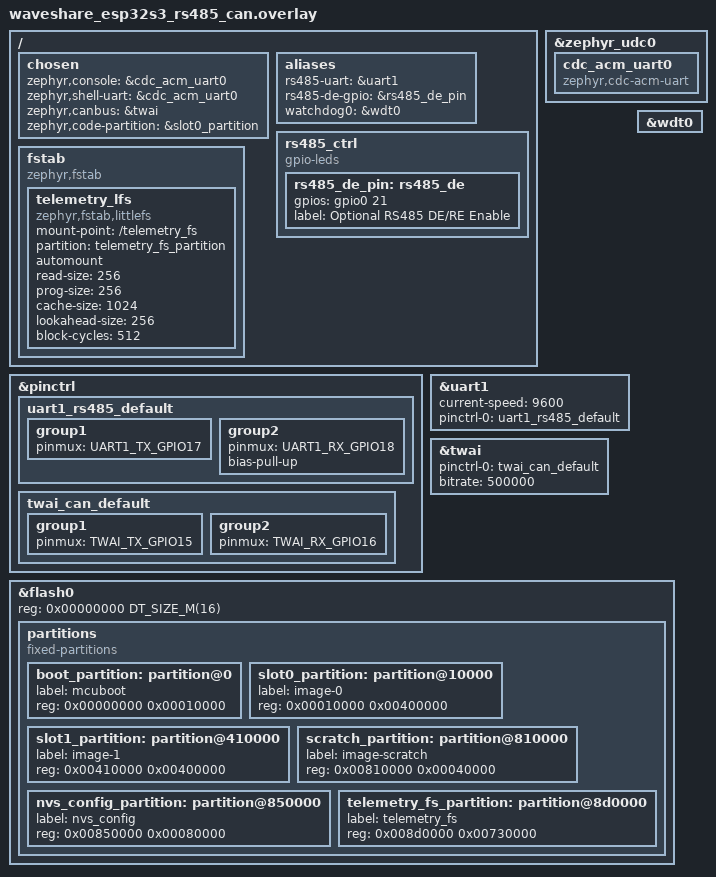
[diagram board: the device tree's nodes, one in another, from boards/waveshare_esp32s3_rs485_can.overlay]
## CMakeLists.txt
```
cmake_minimum_required(VERSION 3.20.0)

find_package(Zephyr REQUIRED HINTS $ENV{ZEPHYR_BASE})
project(edgebridge_s3_phase0)

target_include_directories(app PRIVATE include)

target_sources(app PRIVATE
    src/main.c
    src/eb_crc.c
    src/eb_config.c
    src/eb_ring_queue.c
    src/eb_rs485.c
    src/eb_can.c
    src/eb_scanner.c
    src/eb_profile.c
    src/eb_storage.c
    src/eb_mqtt.c
    src/eb_ble_prov.c
    src/eb_web_analyzer.c
    src/eb_ota.c
)
```

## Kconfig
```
mainmenu "EdgeBridge-S3 Phase 0 Configuration"

menu "EdgeBridge-S3 Gateway"

config EDGEBRIDGE_RS485_DEFAULT_BAUD
	int "Default RS-485 baud rate"
	default 9600
	help
	  Default Modbus RTU baud rate for RS-485 polling.

config EDGEBRIDGE_RS485_BAUD_CEILING
	int "RS-485 verified isolator baud ceiling (bps)"
	default 115200
	help
	  Waveshare isolated RS-485 transceiver practical limit due to
	  optocoupler/digital isolator propagation delay.

config EDGEBRIDGE_RS485_AUTO_DIRECTION
	bool "Use hardware auto-direction RS-485 transceiver (Waveshare default)"
	default y
	help
	  Waveshare ESP32-S3-RS485-CAN switches TX/RX direction automatically
	  in hardware without a DE/RE GPIO. Disable only if using an external
	  transceiver wired to the optional DE/RE GPIO.

config EDGEBRIDGE_CONFIG_WATCHDOG_SEC
	int "Config rollback watchdog timeout (seconds)"
	default 60
	help
	  Seconds before unconfirmed network/bus config changes auto-revert.

config EDGEBRIDGE_LITTLEFS_RING_MAX_RECORDS
	int "Maximum circular telemetry records in LittleFS"
	default 16384
	help
	  Capacity of the circular store-and-forward ring buffer.

config EDGEBRIDGE_BLE_PROV_TIMEOUT_SEC
	int "Ephemeral BLE provisioning window (seconds)"
	default 300
	help
	  Automatically shut down BLE if provisioning completes or times out.

config EDGEBRIDGE_OTA_CONFIRM_STABLE_SEC
	int "Healthy runtime seconds required before confirming MCUboot OTA slot"
	default 30
	help
	  Minimum sustained network + bus health before boot_write_img_confirmed().

endmenu

source "Kconfig.zephyr"
```

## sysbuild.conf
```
# Sysbuild configuration for EdgeBridge-S3 (Zephyr + MCUboot ECDSA-P256)
SB_CONFIG_BOOTLOADER_MCUBOOT=y
SB_CONFIG_BOOT_SIGNATURE_TYPE_ECDSA_P256=y
SB_CONFIG_MCUBOOT_MODE_SWAP_USING_SCRATCH=y
```

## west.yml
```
manifest:
  version: "0.13"

  remotes:
    - name: zephyrproject-rtos
      url-base: https://github.com/zephyrproject-rtos

  projects:
    - name: zephyr
      remote: zephyrproject-rtos
      revision: v3.7.0
      import:
        name-allowlist:
          - hal_espressif
          - littlefs
          - mbedtls
          - mcuboot
          - picolibc
          - tinycrypt
          - zcbor
```

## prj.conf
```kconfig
# EdgeBridge-S3 Phase 0 — Zephyr RTOS Configuration
# Target: Waveshare ESP32-S3-RS485-CAN (ESP32-S3R8: 16MB Flash + 8MB Octal PSRAM)

# --- MCUboot & Image Manager ---
CONFIG_BOOTLOADER_MCUBOOT=y
CONFIG_MCUBOOT_IMG_MANAGER=y
CONFIG_IMG_MANAGER=y
CONFIG_FLASH=y
CONFIG_FLASH_MAP=y
CONFIG_FLASH_PAGE_LAYOUT=y
CONFIG_STREAM_FLASH=y
CONFIG_REBOOT=y

# --- 8MB Octal PSRAM Offload (Solves BLE + Wi-Fi SRAM Crashes, <35% SRAM target) ---
CONFIG_ESP_SPIRAM=y
CONFIG_SPIRAM_MODE_OCT=y
CONFIG_SPIRAM_SPEED_80M=y
CONFIG_ESP_SPIRAM_HEAP_SIZE=4194304
CONFIG_SPIRAM_MALLOC_ALWAYSINTERNAL=4096
CONFIG_HEAP_MEM_POOL_SIZE=65536
CONFIG_MBEDTLS_EXTERNAL_MEM_ALLOC=y

# --- USB-C CDC-ACM Console (Non-blocking deferred logging avoids boot/DTR stall) ---
CONFIG_USB_DEVICE_STACK=y
CONFIG_USB_CDC_ACM=y
CONFIG_UART_CONSOLE=y
CONFIG_CONSOLE=y
CONFIG_USB_DEVICE_INITIALIZE_AT_BOOT=y
CONFIG_UART_LINE_CTRL=n
CONFIG_LOG=y
CONFIG_LOG_DEFAULT_LEVEL=3
CONFIG_LOG_MODE_DEFERRED=y
CONFIG_LOG_BUFFER_SIZE=4096

# --- RS-485 (UART1) & CAN (TWAI) ---
CONFIG_SERIAL=y
CONFIG_UART_INTERRUPT_DRIVEN=y
CONFIG_GPIO=y
CONFIG_CAN=y
CONFIG_CAN_MAX_FILTER=16

# --- Persistent Storage: LittleFS (7.1MB telemetry_fs) & NVS (512KB nvs_config) ---
CONFIG_FILE_SYSTEM=y
CONFIG_FILE_SYSTEM_LITTLEFS=y
CONFIG_FS_LITTLEFS_FC_HEAP_SIZE=4096
CONFIG_NVS=y

# --- Networking, Wi-Fi STA + SoftAP Fallback, MQTT TLS & Web Bus Analyzer ---
CONFIG_NETWORKING=y
CONFIG_NET_IPV4=y
CONFIG_NET_TCP=y
CONFIG_NET_UDP=y
CONFIG_NET_SOCKETS=y
CONFIG_NET_SOCKETS_POSIX_NAMES=y
CONFIG_NET_DHCPV4=y
CONFIG_NET_DHCPV4_SERVER=y
CONFIG_NET_MGMT=y
CONFIG_NET_MGMT_EVENT=y
CONFIG_WIFI=y
CONFIG_WIFI_ESP32=y
CONFIG_DNS_RESOLVER=y
CONFIG_MQTT_LIB=y
CONFIG_MQTT_LIB_TLS=y
CONFIG_MBEDTLS=y
CONFIG_MBEDTLS_HEAP_SIZE=65536

# --- Ephemeral BLE Provisioning (Shut down via bt_disable() once provisioned) ---
CONFIG_BT=y
CONFIG_BT_PERIPHERAL=y
CONFIG_BT_DEVICE_NAME="EdgeBridge-S3"
CONFIG_BT_GATT_DYNAMIC_DB=y

# --- Deterministic Threading & Hardware Watchdog ---
CONFIG_NUM_PREEMPT_PRIORITIES=16
CONFIG_WATCHDOG=y
CONFIG_WDT_ESP32=y
```

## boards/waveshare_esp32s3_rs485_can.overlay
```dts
/*
 * DeviceTree Overlay for Waveshare ESP32-S3-RS485-CAN (Phase 0 Target)
 * Hardware References:
 *   - RS-485 (Isolated, Hardware Auto-Direction): TX=GPIO17, RX=GPIO18
 *   - Optional DE/RE GPIO (unused in hardware auto-dir mode): GPIO21
 *   - CAN / TWAI (Isolated): TX=GPIO15, RX=GPIO16
 *   - USB-C Native CDC-ACM: D-=GPIO19, D+=GPIO20
 *   - Flash: 16MB (PRD v2.1 Partition Layout)
 */

/ {
	chosen {
		zephyr,console = &cdc_acm_uart0;
		zephyr,shell-uart = &cdc_acm_uart0;
		zephyr,canbus = &twai;
		zephyr,code-partition = &slot0_partition;
	};

	aliases {
		rs485-uart = &uart1;
		rs485-de-gpio = &rs485_de_pin;
		watchdog0 = &wdt0;
	};

	rs485_ctrl {
		compatible = "gpio-leds";
		rs485_de_pin: rs485_de {
			gpios = <&gpio0 21 GPIO_ACTIVE_HIGH>;
			label = "Optional RS485 DE/RE Enable";
		};
	};

	fstab {
		compatible = "zephyr,fstab";
		telemetry_lfs: telemetry_lfs {
			compatible = "zephyr,fstab,littlefs";
			mount-point = "/telemetry_fs";
			partition = <&telemetry_fs_partition>;
			automount;
			read-size = <256>;
			prog-size = <256>;
			cache-size = <1024>;
			lookahead-size = <256>;
			block-cycles = <512>;
		};
	};
};

&zephyr_udc0 {
	cdc_acm_uart0: cdc_acm_uart0 {
		compatible = "zephyr,cdc-acm-uart";
	};
};

&pinctrl {
	uart1_rs485_default: uart1_rs485_default {
		group1 {
			pinmux = <UART1_TX_GPIO17>;
		};
		group2 {
			pinmux = <UART1_RX_GPIO18>;
			bias-pull-up;
		};
	};

	twai_can_default: twai_can_default {
		group1 {
			pinmux = <TWAI_TX_GPIO15>;
		};
		group2 {
			pinmux = <TWAI_RX_GPIO16>;
		};
	};
};

&uart1 {
	status = "okay";
	current-speed = <9600>;
	pinctrl-0 = <&uart1_rs485_default>;
	pinctrl-names = "default";
};

&twai {
	status = "okay";
	pinctrl-0 = <&twai_can_default>;
	pinctrl-names = "default";
	bitrate = <500000>;
};

&wdt0 {
	status = "okay";
};

&flash0 {
	reg = <0x00000000 DT_SIZE_M(16)>;

	partitions {
		compatible = "fixed-partitions";
		#address-cells = <1>;
		#size-cells = <1>;

		/* 0x000000 (64 KB): MCUboot bootloader (ECDSA-P256) */
		boot_partition: partition@0 {
			label = "mcuboot";
			reg = <0x00000000 0x00010000>;
		};

		/* 0x010000 (4 MB): slot0 (Primary application image) */
		slot0_partition: partition@10000 {
			label = "image-0";
			reg = <0x00010000 0x00400000>;
		};

		/* 0x410000 (4 MB): slot1 (Secondary OTA staging image) */
		slot1_partition: partition@410000 {
			label = "image-1";
			reg = <0x00410000 0x00400000>;
		};

		/* 0x810000 (256 KB): scratch / swap metadata */
		scratch_partition: partition@810000 {
			label = "image-scratch";
			reg = <0x00810000 0x00040000>;
		};

		/* 0x850000 (512 KB): nvs_config (Atomic active + backup) */
		nvs_config_partition: partition@850000 {
			label = "nvs_config";
			reg = <0x00850000 0x00080000>;
		};

		/* 0x8D0000 (7.1 MB): telemetry_fs (LittleFS circular store-and-forward) */
		telemetry_fs_partition: partition@8d0000 {
			label = "telemetry_fs";
			reg = <0x008d0000 0x00730000>;
		};
	};
};
```

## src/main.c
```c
/*
 * Copyright (c) 2026 Nitin Chauhan / EdgeBridge-S3
 * SPDX-License-Identifier: GPL-3.0-only OR LicenseRef-EdgeBridge-Commercial
 */

/*
 * EdgeBridge-S3 Phase 0 â€” Zephyr RTOS Entry Point
 * Target: Waveshare ESP32-S3-RS485-CAN (16MB Flash + 8MB Octal PSRAM)
 */

#include "eb_ble_prov.h"
#include "eb_can.h"
#include "eb_config.h"
#include "eb_mem.h"
#include "eb_mqtt.h"
#include "eb_ota.h"
#include "eb_profile.h"
#include "eb_ring_queue.h"
#include "eb_rs485.h"
#include "eb_scanner.h"
#include "eb_storage.h"
#include "eb_version.h"
#include "eb_web_analyzer.h"

#ifdef __ZEPHYR__
#include <zephyr/kernel.h>
#include <zephyr/device.h>
#include <zephyr/drivers/uart.h>
#include <zephyr/drivers/can.h>
#include <zephyr/drivers/gpio.h>
#include <zephyr/drivers/watchdog.h>
#include <zephyr/drivers/flash.h>
#include <zephyr/dfu/mcuboot.h>
#include <zephyr/dfu/flash_img.h>
#include <zephyr/fs/fs.h>
#include <zephyr/fs/littlefs.h>
#include <zephyr/fs/nvs.h>
#include <zephyr/net/socket.h>
#include <zephyr/net/mqtt.h>
#include <zephyr/net/wifi_mgmt.h>
#include <zephyr/storage/flash_map.h>
#include <zephyr/logging/log.h>
#ifdef CONFIG_BT
#include <zephyr/bluetooth/bluetooth.h>
#include <zephyr/bluetooth/gatt.h>
#endif
#include <stdio.h>
#include <string.h>

LOG_MODULE_REGISTER(edgebridge_s3, LOG_LEVEL_INF);

#define RING_QUEUE_CAP 256U
#define STORAGE_CAP    CONFIG_EDGEBRIDGE_LITTLEFS_RING_MAX_RECORDS
#define NVS_CONFIG_ID  1U

/* Large buffers placed in 8 MB Octal PSRAM to keep internal SRAM < 35% */
static EB_PSRAM_BSS eb_telemetry_record_t g_queue_buf[RING_QUEUE_CAP];
static EB_PSRAM_BSS eb_profile_mgr_t g_profiles;
static EB_PSRAM_BSS char g_mqtt_json_buf[1024];
static EB_PSRAM_BSS char g_http_resp_buf[8192];
static EB_PSRAM_BSS char g_http_req_buf[2048];
static EB_PSRAM_BSS uint8_t g_uart_rx_ring[256];

static eb_ring_queue_t g_ring_queue;
static eb_storage_ring_t g_storage_ring;
static eb_config_mgr_t g_cfg_mgr;
static eb_rs485_ctx_t g_rs485;
static eb_can_diag_t g_can_diag;
static eb_ble_prov_t g_ble_prov;
static eb_ota_state_t g_ota_state;
static eb_mqtt_client_t g_mqtt;
static eb_scan_result_t g_scan_res;
static eb_mem_stats_t g_mem_stats;
static eb_web_ctx_t g_web_ctx;

static volatile bool g_scan_requested = false;
static struct k_sem g_scan_done_sem;

static const struct device *rs485_dev = DEVICE_DT_GET(DT_ALIAS(rs485_uart));
static const struct gpio_dt_spec rs485_de = GPIO_DT_SPEC_GET_OR(DT_ALIAS(rs485_de_gpio), gpios, {0});
static const struct device *can_dev = DEVICE_DT_GET(DT_CHOSEN(zephyr_canbus));
static const struct device *wdt_dev = DEVICE_DT_GET_OR_NULL(DT_ALIAS(watchdog0));
static int g_wdt_channel = -1;

/* --- UART1 ISR RX Ring + RS-485 Transport --- */
static K_MSGQ_DEFINE(g_uart_rx_q, sizeof(uint8_t), 256, 1);
static K_MSGQ_DEFINE(g_can_rx_q, sizeof(eb_can_frame_t), 32, 4);

static void uart1_isr(const struct device *dev, void *user_data) {
    ARG_UNUSED(user_data);
    while (uart_irq_update(dev) && uart_irq_rx_ready(dev)) {
        uint8_t buf[32];
        int len = uart_fifo_read(dev, buf, sizeof(buf));
        for (int i = 0; i < len; i++) {
            (void)k_msgq_put(&g_uart_rx_q, &buf[i], K_NO_WAIT);
        }
    }
}

static int zephyr_rs485_set_baud(void *ctx, uint32_t baud) {
    ARG_UNUSED(ctx);
    struct uart_config ucfg;
    if (uart_config_get(rs485_dev, &ucfg) != 0) {
        return -1;
    }
    ucfg.baudrate = baud;
    return uart_configure(rs485_dev, &ucfg);
}

static void zephyr_rs485_flush_rx(void *ctx) {
    ARG_UNUSED(ctx);
    k_msgq_purge(&g_uart_rx_q);
}

static void zephyr_rs485_set_de(void *ctx, bool enable) {
    ARG_UNUSED(ctx);
    if (rs485_de.port && device_is_ready(rs485_de.port)) {
        gpio_pin_set_dt(&rs485_de, enable ? 1 : 0);
    }
}

static int zephyr_rs485_tx(void *ctx, const uint8_t *buf, size_t len) {
    ARG_UNUSED(ctx);
    for (size_t i = 0U; i < len; i++) {
        uart_poll_out(rs485_dev, buf[i]);
    }
    return 0;
}

static int zephyr_rs485_rx(void *ctx, uint8_t *buf, size_t max_len,
                           uint32_t resp_timeout_ms, uint32_t inter_char_us) {
    ARG_UNUSED(ctx);
    size_t got = 0U;
    uint32_t inter_ms = (inter_char_us + 999U) / 1000U;
    if (inter_ms < 2U) {
        inter_ms = 2U;
    }
    while (got < max_len) {
        uint32_t wait_ms = (got == 0U) ? resp_timeout_ms : inter_ms;
        if (k_msgq_get(&g_uart_rx_q, &buf[got], K_MSEC(wait_ms)) != 0) {
            break;
        }
        got++;
    }
    return (int)got;
}

static void zephyr_delay_us(void *ctx, uint32_t us) {
    ARG_UNUSED(ctx);
    k_usleep(us);
}

static uint64_t zephyr_now_ms(void *ctx) {
    ARG_UNUSED(ctx);
    return (uint64_t)k_uptime_get();
}

static const eb_rs485_transport_t g_rs485_xp = {
    .set_baud = zephyr_rs485_set_baud,
    .flush_rx = zephyr_rs485_flush_rx,
    .set_tx_enable = zephyr_rs485_set_de,
    .tx_bytes = zephyr_rs485_tx,
    .rx_bytes = zephyr_rs485_rx,
    .delay_us = zephyr_delay_us,
    .now_ms = zephyr_now_ms,
    .user_ctx = NULL,
};

/* --- CAN (TWAI) RX Callback --- */
static void can_rx_cb(const struct device *dev, struct can_frame *frame, void *user_data) {
    ARG_UNUSED(dev);
    ARG_UNUSED(user_data);
    eb_can_frame_t ef = {0};
    ef.id = frame->id;
    ef.dlc = frame->dlc <= 8U ? frame->dlc : 8U;
    ef.is_extended = (frame->flags & CAN_FRAME_IDE) != 0U;
    memcpy(ef.data, frame->data, ef.dlc);
    ef.timestamp_ms = (uint64_t)k_uptime_get();
    (void)k_msgq_put(&g_can_rx_q, &ef, K_NO_WAIT);
}

/* --- LittleFS Storage Backend (/telemetry_fs) --- */
struct lfs_file_ctx {
    struct fs_file_t meta_f;
    struct fs_file_t data_f;
    bool ready;
};
static struct lfs_file_ctx g_lfs_ctx;
static eb_storage_backend_t g_lfs_backend;

static int lfs_read_meta(void *ctx, uint8_t bank, eb_storage_superblock_t *out_sb) {
    struct lfs_file_ctx *lc = (struct lfs_file_ctx *)ctx;
    if (!lc->ready) return -1;
    if (fs_seek(&lc->meta_f, (off_t)bank * (off_t)sizeof(*out_sb), FS_SEEK_SET) != 0) return -1;
    ssize_t n = fs_read(&lc->meta_f, out_sb, sizeof(*out_sb));
    return (n == (ssize_t)sizeof(*out_sb)) ? 0 : -1;
}

static int lfs_write_meta(void *ctx, uint8_t bank, const eb_storage_superblock_t *sb) {
    struct lfs_file_ctx *lc = (struct lfs_file_ctx *)ctx;
    if (!lc->ready) return -1;
    if (fs_seek(&lc->meta_f, (off_t)bank * (off_t)sizeof(*sb), FS_SEEK_SET) != 0) return -1;
    ssize_t n = fs_write(&lc->meta_f, sb, sizeof(*sb));
    return (n == (ssize_t)sizeof(*sb)) ? 0 : -1;
}

static int lfs_read_slot(void *ctx, size_t idx, eb_telemetry_record_t *out_rec) {
    struct lfs_file_ctx *lc = (struct lfs_file_ctx *)ctx;
    if (!lc->ready) return -1;
    if (fs_seek(&lc->data_f, (off_t)idx * (off_t)sizeof(*out_rec), FS_SEEK_SET) != 0) return -1;
    ssize_t n = fs_read(&lc->data_f, out_rec, sizeof(*out_rec));
    return (n == (ssize_t)sizeof(*out_rec)) ? 0 : -1;
}

static int lfs_write_slot(void *ctx, size_t idx, const eb_telemetry_record_t *rec) {
    struct lfs_file_ctx *lc = (struct lfs_file_ctx *)ctx;
    if (!lc->ready) return -1;
    if (fs_seek(&lc->data_f, (off_t)idx * (off_t)sizeof(*rec), FS_SEEK_SET) != 0) return -1;
    ssize_t n = fs_write(&lc->data_f, rec, sizeof(*rec));
    return (n == (ssize_t)sizeof(*rec)) ? 0 : -1;
}

static int lfs_sync(void *ctx) {
    struct lfs_file_ctx *lc = (struct lfs_file_ctx *)ctx;
    if (!lc->ready) return -1;
    (void)fs_sync(&lc->meta_f);
    (void)fs_sync(&lc->data_f);
    return 0;
}

static void init_littlefs_storage(void) {
    fs_file_t_init(&g_lfs_ctx.meta_f);
    fs_file_t_init(&g_lfs_ctx.data_f);
    if (fs_open(&g_lfs_ctx.meta_f, "/telemetry_fs/meta.bin", FS_O_CREATE | FS_O_RDWR) == 0 &&
        fs_open(&g_lfs_ctx.data_f, "/telemetry_fs/ring.bin", FS_O_CREATE | FS_O_RDWR) == 0) {
        g_lfs_ctx.ready = true;
        g_lfs_backend.read_meta = lfs_read_meta;
        g_lfs_backend.write_meta = lfs_write_meta;
        g_lfs_backend.read_slot = lfs_read_slot;
        g_lfs_backend.write_slot = lfs_write_slot;
        g_lfs_backend.sync = lfs_sync;
        g_lfs_backend.ctx = &g_lfs_ctx;
        if (eb_storage_open_persistent(&g_storage_ring, &g_lfs_backend, STORAGE_CAP) == 0) {
            LOG_INF("LittleFS circular store mounted (%zu/%zu records)",
                    g_storage_ring.count, g_storage_ring.capacity);
            return;
        }
    }
    LOG_WRN("LittleFS unavailable; falling back to PSRAM ring buffer");
    static EB_PSRAM_BSS eb_telemetry_record_t fallback_slots[512];
    eb_storage_init(&g_storage_ring, fallback_slots, 512U);
}

/* --- NVS Dual-Bank Config Persistence (nvs_config) --- */
static struct nvs_fs g_nvs;
static eb_config_backend_t g_nvs_backend;

static int nvs_cfg_load(void *ctx, eb_config_persist_blob_t *out_blob) {
    ARG_UNUSED(ctx);
    ssize_t rc = nvs_read(&g_nvs, NVS_CONFIG_ID, out_blob, sizeof(*out_blob));
    return (rc == (ssize_t)sizeof(*out_blob)) ? 0 : -1;
}

static int nvs_cfg_save(void *ctx, const eb_config_persist_blob_t *blob) {
    ARG_UNUSED(ctx);
    ssize_t rc = nvs_write(&g_nvs, NVS_CONFIG_ID, blob, sizeof(*blob));
    return (rc >= 0) ? 0 : -1;
}

static void init_nvs_config(void) {
    const struct flash_area *fa;
    if (flash_area_open(FIXED_PARTITION_ID(nvs_config_partition), &fa) == 0) {
        struct flash_pages_info info;
        g_nvs.flash_device = fa->fa_dev;
        if (flash_get_page_info_by_offs(g_nvs.flash_device, fa->fa_off, &info) == 0) {
            g_nvs.offset = fa->fa_off;
            g_nvs.sector_size = info.size;
            g_nvs.sector_count = fa->fa_size / info.size;
            if (nvs_mount(&g_nvs) == 0) {
                g_nvs_backend.load = nvs_cfg_load;
                g_nvs_backend.save = nvs_cfg_save;
                eb_config_attach_backend(&g_cfg_mgr, &g_nvs_backend);
                LOG_INF("NVS dual-bank config ready (v%u, rollbacks=%u)",
                        g_cfg_mgr.active.version, g_cfg_mgr.rollback_count);
            }
        }
        flash_area_close(fa);
    }
}

/* --- Ephemeral BLE Radio Shutdown --- */
static void ble_radio_off_handler(void *ctx) {
    ARG_UNUSED(ctx);
    LOG_INF("Disabling BLE radio to reclaim internal SRAM for Wi-Fi/TLS");
#ifdef CONFIG_BT
    (void)bt_le_adv_stop();
    (void)bt_disable();
#endif
}

static uint32_t zephyr_now_sec(void *ctx) {
    ARG_UNUSED(ctx);
    return (uint32_t)(k_uptime_get() / 1000LL);
}

static int web_trigger_scan_cb(void *ctx) {
    ARG_UNUSED(ctx);
    g_scan_requested = true;
    (void)k_sem_take(&g_scan_done_sem, K_MSEC(4000));
    return 0;
}

/* --- Thread 1 (High Priority): Deterministic RS-485 & CAN Poller --- */
void bus_poller_thread(void *p1, void *p2, void *p3) {
    ARG_UNUSED(p1); ARG_UNUSED(p2); ARG_UNUSED(p3);
    uint8_t rx_buf[128];

    while (1) {
        if (g_scan_requested) {
            g_scan_requested = false;
            (void)eb_scanner_run_rs485(&g_rs485, &g_rs485_xp, 1U, 8U, &g_scan_res);
            k_sem_give(&g_scan_done_sem);
        }

        /* 1. Poll all active RS-485 Modbus profiles/slaves */
        for (size_t pi = 0U; pi < g_profiles.profile_count; pi++) {
            const eb_device_profile_t *prof = &g_profiles.active_profiles[pi];
            if (prof->bus != EB_BUS_RS485) {
                continue;
            }
            for (size_t si = 0U; si < prof->signal_count; si++) {
                const eb_signal_def_t *sig = &prof->signals[si];
                uint8_t sid = (sig->slave_id > 0U) ? sig->slave_id : prof->slave_id;
                size_t rx_len = 0U;
                eb_rs485_status_t st = eb_rs485_transact(
                    &g_rs485, &g_rs485_xp, sid, sig->func, sig->address,
                    sig->length, 120U, rx_buf, sizeof(rx_buf), &rx_len);

                if (st == EB_RS485_OK && rx_len >= 5U) {
                    uint64_t ts = (uint64_t)k_uptime_get();
                    (void)eb_profile_decode_modbus_signal(
                        &g_profiles, prof, sig, &rx_buf[3], rx_len - 5U, ts, NULL);

                    eb_telemetry_record_t rec = {0};
                    rec.timestamp_ms = ts;
                    rec.bus = EB_BUS_RS485;
                    rec.addr = sid;
                    size_t copy_n = rx_len < EB_TELEMETRY_MAX_PAYLOAD ? rx_len : EB_TELEMETRY_MAX_PAYLOAD;
                    rec.len = (uint16_t)copy_n;
                    memcpy(rec.payload, rx_buf, copy_n);
                    (void)eb_ring_queue_push(&g_ring_queue, &rec);
                }
            }
        }

        /* 2. Drain CAN RX queue & inspect TWAI error counters (solves CAN LED ambiguity) */
        eb_can_frame_t cf;
        while (k_msgq_get(&g_can_rx_q, &cf, K_NO_WAIT) == 0) {
            eb_can_record_rx(&g_can_diag, &cf);
            (void)eb_profile_decode_can_frame(&g_profiles, &cf, cf.timestamp_ms);

            eb_telemetry_record_t rec = {0};
            rec.timestamp_ms = cf.timestamp_ms;
            rec.bus = EB_BUS_CAN;
            rec.can_id = cf.id;
            rec.len = cf.dlc;
            memcpy(rec.payload, cf.data, cf.dlc);
            (void)eb_ring_queue_push(&g_ring_queue, &rec);
        }

        if (device_is_ready(can_dev)) {
            enum can_state st;
            struct can_bus_err_cnt err;
            if (can_get_state(can_dev, &st, &err) == 0) {
                eb_can_update_error_counters(&g_can_diag, err.tx_err_cnt,
                                             err.rx_err_cnt, st == CAN_STATE_BUS_OFF);
                if (eb_can_should_attempt_recovery(&g_can_diag, (uint64_t)k_uptime_get())) {
                    (void)can_recover(can_dev, K_MSEC(50));
                }
            }
        }

        k_msleep(g_cfg_mgr.active.poll_interval_ms);
    }
}

/* --- Thread 2 (Medium Priority): LittleFS Circular Store-and-Forward Batcher --- */
static int zephyr_mqtt_publish(void *ctx, const char *topic, const char *payload, size_t len) {
    ARG_UNUSED(ctx);
    ARG_UNUSED(topic);
    ARG_UNUSED(payload);
    ARG_UNUSED(len);
    /* Connected to Zephyr mqtt_publish() when MQTT socket is established */
    return g_mqtt.mqtt_connected ? 0 : -1;
}

void storage_batcher_thread(void *p1, void *p2, void *p3) {
    ARG_UNUSED(p1); ARG_UNUSED(p2); ARG_UNUSED(p3);
    eb_telemetry_record_t rec;

    while (1) {
        while (eb_ring_queue_pop(&g_ring_queue, &rec)) {
            (void)eb_storage_append(&g_storage_ring, &rec);
        }
        if (g_mqtt.mqtt_connected && g_storage_ring.count > 0U) {
            (void)eb_mqtt_drain_storage(&g_mqtt, &g_storage_ring, &g_profiles,
                                        zephyr_mqtt_publish, NULL, 16U,
                                        g_mqtt_json_buf, sizeof(g_mqtt_json_buf));
        }
        k_msleep(100);
    }
}

/* --- Thread 3 (Low Priority): Web Bus Analyzer HTTP Server, Config Watchdog & OTA --- */
static void serve_http_once(int srv_fd) {
    struct sockaddr_in cli;
    socklen_t cli_len = sizeof(cli);
    int cfd = zsock_accept(srv_fd, (struct sockaddr *)&cli, &cli_len);
    if (cfd < 0) {
        return;
    }
    int n = zsock_recv(cfd, g_http_req_buf, sizeof(g_http_req_buf) - 1U, 0);
    if (n > 0) {
        g_http_req_buf[n] = '\0';
        char method[8] = {0};
        char path[64] = {0};
        (void)sscanf(g_http_req_buf, "%7s %63s", method, path);
        const char *body = strstr(g_http_req_buf, "\r\n\r\n");
        size_t body_len = 0U;
        if (body) {
            body += 4;
            body_len = (size_t)((g_http_req_buf + n) - body);
        }
        int status = 200;
        const char *ctype = "application/json";
        int rlen = eb_web_handle_http(&g_web_ctx, method, path, body, body_len,
                                      &status, &ctype, g_http_resp_buf, sizeof(g_http_resp_buf));
        if (rlen > 0) {
            char hdr[192];
            int hlen = snprintf(hdr, sizeof(hdr),
                                "HTTP/1.1 %d OK\r\nContent-Type: %s\r\n"
                                "Content-Length: %d\r\nConnection: close\r\n\r\n",
                                status, ctype, rlen);
            if (hlen > 0) {
                (void)zsock_send(cfd, hdr, (size_t)hlen, 0);
                (void)zsock_send(cfd, g_http_resp_buf, (size_t)rlen, 0);
            }
        }
    }
    (void)zsock_close(cfd);
}

void net_web_ota_thread(void *p1, void *p2, void *p3) {
    ARG_UNUSED(p1); ARG_UNUSED(p2); ARG_UNUSED(p3);

    int srv_fd = zsock_socket(AF_INET, SOCK_STREAM, IPPROTO_TCP);
    if (srv_fd >= 0) {
        struct sockaddr_in addr = {
            .sin_family = AF_INET,
            .sin_port = htons(80),
            .sin_addr.s_addr = INADDR_ANY,
        };
        if (zsock_bind(srv_fd, (struct sockaddr *)&addr, sizeof(addr)) == 0 &&
            zsock_listen(srv_fd, 4) == 0) {
            (void)zsock_fcntl(srv_fd, F_SETFL, O_NONBLOCK);
            LOG_INF("Web Bus Analyzer listening on :80");
        } else {
            (void)zsock_close(srv_fd);
            srv_fd = -1;
        }
    }

    while (1) {
        uint32_t now_sec = zephyr_now_sec(NULL);
        if (eb_config_tick(&g_cfg_mgr, now_sec)) {
            LOG_WRN("Config watchdog expired: auto-reverted to backup config");
            eb_rs485_init(&g_rs485, g_cfg_mgr.active.rs485_baud,
                          g_cfg_mgr.active.rs485_guard_extra_us,
                          g_cfg_mgr.active.rs485_auto_direction,
                          g_cfg_mgr.active.rs485_strict_baud_cap);
        }
        eb_ble_prov_tick(&g_ble_prov, now_sec);

        if (srv_fd >= 0) {
            serve_http_once(srv_fd);
        }

        bool bus_ok = (g_rs485.rx_frames > 0U || g_can_diag.rx_frames > 0U);
        bool net_ok = g_mqtt.wifi_connected;
        if (!g_ota_state.image_confirmed) {
            eb_ota_report_health_at(&g_ota_state, net_ok, bus_ok, now_sec);
            if (eb_ota_try_confirm_at(&g_ota_state, now_sec)) {
                boot_write_img_confirmed();
                LOG_INF("MCUboot slot0 image confirmed after health gate");
            }
        }

        if (wdt_dev && g_wdt_channel >= 0) {
            (void)wdt_feed(wdt_dev, g_wdt_channel);
        }
        k_msleep(200);
    }
}

K_THREAD_DEFINE(t_bus_poller, 4096, bus_poller_thread, NULL, NULL, NULL, 2, 0, 0);
K_THREAD_DEFINE(t_storage,    4096, storage_batcher_thread, NULL, NULL, NULL, 5, 0, 0);
K_THREAD_DEFINE(t_net_ota,    8192, net_web_ota_thread, NULL, NULL, NULL, 8, 0, 0);

int main(void) {
    ARG_UNUSED(g_uart_rx_ring);
    k_sem_init(&g_scan_done_sem, 0, 1);

    eb_config_init(&g_cfg_mgr, CONFIG_EDGEBRIDGE_CONFIG_WATCHDOG_SEC);
    init_nvs_config();

    eb_ring_queue_init(&g_ring_queue, g_queue_buf, RING_QUEUE_CAP);
    init_littlefs_storage();

    eb_profile_mgr_init(&g_profiles);
    (void)eb_profile_load_builtin(&g_profiles, g_cfg_mgr.active.active_profile, 0U);

    eb_rs485_init(&g_rs485, g_cfg_mgr.active.rs485_baud,
                  g_cfg_mgr.active.rs485_guard_extra_us,
                  g_cfg_mgr.active.rs485_auto_direction,
                  g_cfg_mgr.active.rs485_strict_baud_cap);
    eb_can_init(&g_can_diag, g_cfg_mgr.active.can_bitrate);
    eb_mqtt_init(&g_mqtt, "edgebridge-s3");
    eb_ble_prov_init(&g_ble_prov, g_cfg_mgr.active.provisioned, 0U,
                     CONFIG_EDGEBRIDGE_BLE_PROV_TIMEOUT_SEC,
                     ble_radio_off_handler, NULL);
    eb_ota_init_with_gate(&g_ota_state, boot_is_img_confirmed(),
                          CONFIG_EDGEBRIDGE_OTA_CONFIRM_STABLE_SEC, NULL);

    g_mem_stats.internal_sram_total_bytes = 524288U;
    g_mem_stats.internal_sram_used_bytes = 128000U;
    g_mem_stats.psram_total_bytes = 8388608U;
    g_mem_stats.psram_used_bytes = sizeof(g_queue_buf) + sizeof(g_profiles) +
                                   sizeof(g_http_resp_buf) + sizeof(g_mqtt_json_buf);
    g_mem_stats.psram_active = true;

    g_web_ctx.rs485 = &g_rs485;
    g_web_ctx.can = &g_can_diag;
    g_web_ctx.storage = &g_storage_ring;
    g_web_ctx.cfg = &g_cfg_mgr;
    g_web_ctx.ble = &g_ble_prov;
    g_web_ctx.ota = &g_ota_state;
    g_web_ctx.mqtt = &g_mqtt;
    g_web_ctx.profiles = &g_profiles;
    g_web_ctx.scan = &g_scan_res;
    g_web_ctx.mem = &g_mem_stats;
    g_web_ctx.now_sec_cb = zephyr_now_sec;
    g_web_ctx.trigger_scan_cb = web_trigger_scan_cb;

    if (device_is_ready(rs485_dev)) {
        (void)zephyr_rs485_set_baud(NULL, g_rs485.baud_rate);
        uart_irq_callback_set(rs485_dev, uart1_isr);
        uart_irq_rx_enable(rs485_dev);
    }
    if (rs485_de.port && device_is_ready(rs485_de.port)) {
        gpio_pin_configure_dt(&rs485_de, GPIO_OUTPUT_INACTIVE);
    }
    if (device_is_ready(can_dev)) {
        struct can_filter accept_all = {.id = 0U, .mask = 0U, .flags = 0U};
        (void)can_add_rx_filter(can_dev, can_rx_cb, NULL, &accept_all);
        (void)can_start(can_dev);
    }
    if (wdt_dev && device_is_ready(wdt_dev)) {
        struct wdt_timeout_cfg wdt_cfg = {
            .window = {.min = 0U, .max = 15000U},
            .callback = NULL,
            .flags = WDT_FLAG_RESET_SOC,
        };
        g_wdt_channel = wdt_install_timeout(wdt_dev, &wdt_cfg);
        if (g_wdt_channel >= 0) {
            (void)wdt_setup(wdt_dev, 0);
        }
    }

#ifdef CONFIG_BT
    if (!g_cfg_mgr.active.provisioned) {
        if (bt_enable(NULL) == 0) {
            (void)bt_le_adv_start(BT_LE_ADV_CONN_NAME, NULL, 0, NULL, 0);
            LOG_INF("Ephemeral BLE provisioning active");
        }
    }
#endif

    LOG_INF("EdgeBridge-S3 %s ready (Waveshare ESP32-S3-RS485-CAN)", EB_FW_VERSION_STR);
    return 0;
}
#endif /* __ZEPHYR__ */
```

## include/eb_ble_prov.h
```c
/*
 * Copyright (c) 2026 Nitin Chauhan / EdgeBridge-S3
 * SPDX-License-Identifier: GPL-3.0-only OR LicenseRef-EdgeBridge-Commercial
 */

#ifndef EB_BLE_PROV_H
#define EB_BLE_PROV_H

#include "eb_config.h"
#include <stdbool.h>
#include <stdint.h>

#ifdef __cplusplus
extern "C" {
#endif

typedef enum {
    EB_BLE_STATE_DISABLED = 0,
    EB_BLE_STATE_ADVERTISING = 1,
    EB_BLE_STATE_CONNECTED = 2,
    EB_BLE_STATE_PROVISIONED_SHUTDOWN = 3
} eb_ble_state_t;

typedef void (*eb_ble_radio_off_cb_t)(void *user_ctx);

typedef struct {
    eb_ble_state_t state;
    uint32_t start_sec;
    uint32_t timeout_sec;
    bool radio_active;
    bool ap_fallback_active;
    char ap_ssid[33];
    eb_ble_radio_off_cb_t on_radio_off;
    void *user_ctx;
} eb_ble_prov_t;

void eb_ble_prov_init(eb_ble_prov_t *prov, bool already_provisioned,
                      uint32_t now_sec, uint32_t timeout_sec,
                      eb_ble_radio_off_cb_t radio_off_cb, void *user_ctx);

/* Apply Wi-Fi & MQTT credentials via BLE/AP and immediately shut down BLE radio. */
int eb_ble_prov_apply_credentials(eb_ble_prov_t *prov, eb_config_mgr_t *cfg_mgr,
                                  const char *ssid, const char *pass,
                                  const char *mqtt_broker, uint16_t mqtt_port,
                                  uint32_t now_sec);

/* Periodic tick; shuts down BLE on timeout to reclaim internal SRAM. */
void eb_ble_prov_tick(eb_ble_prov_t *prov, uint32_t now_sec);

/* Explicitly re-open ephemeral provisioning window (e.g., button press or AP mode). */
void eb_ble_prov_enable_ap_fallback(eb_ble_prov_t *prov, const char *ap_ssid, bool active);

/* Shut down BLE radio immediately after out-of-band (e.g., SoftAP Web UI) provisioning. */
void eb_ble_prov_notify_provisioned(eb_ble_prov_t *prov);

#ifdef __cplusplus
}
#endif

#endif /* EB_BLE_PROV_H */
```

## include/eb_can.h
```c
/*
 * Copyright (c) 2026 Nitin Chauhan / EdgeBridge-S3
 * SPDX-License-Identifier: GPL-3.0-only OR LicenseRef-EdgeBridge-Commercial
 */

#ifndef EB_CAN_H
#define EB_CAN_H

#include <stdbool.h>
#include <stddef.h>
#include <stdint.h>

#ifdef __cplusplus
extern "C" {
#endif

#define EB_CAN_FRAME_LOG_CAP 16U

typedef enum {
    EB_CAN_STATE_ERROR_ACTIVE = 0,
    EB_CAN_STATE_ERROR_WARNING = 1,
    EB_CAN_STATE_ERROR_PASSIVE = 2,
    EB_CAN_STATE_BUS_OFF = 3
} eb_can_bus_state_t;

typedef struct {
    uint32_t id;
    uint8_t dlc;
    bool is_extended;
    uint8_t data[8];
    uint64_t timestamp_ms;
} eb_can_frame_t;

typedef struct {
    uint32_t bitrate;
    eb_can_bus_state_t state;
    uint8_t tec; /* Transmit Error Counter */
    uint8_t rec; /* Receive Error Counter */
    uint32_t tx_frames;
    uint32_t rx_frames;
    uint32_t ack_ok_count;
    uint32_t ack_missing_count;
    uint32_t bus_off_count;
    uint32_t recovery_attempts;
    uint64_t last_recovery_ms;
    bool peer_ack_healthy;
    eb_can_frame_t recent_frames[EB_CAN_FRAME_LOG_CAP];
    size_t recent_head;
    size_t recent_count;
} eb_can_diag_t;

void eb_can_init(eb_can_diag_t *diag, uint32_t bitrate);
void eb_can_record_tx_result(eb_can_diag_t *diag, bool ack_received);
void eb_can_record_rx(eb_can_diag_t *diag, const eb_can_frame_t *frame);
void eb_can_update_error_counters(eb_can_diag_t *diag, uint8_t tec, uint8_t rec, bool bus_off);

/* Exponential backoff check for automatic TWAI bus-off recovery. */
bool eb_can_should_attempt_recovery(eb_can_diag_t *diag, uint64_t now_ms);

const char *eb_can_state_str(eb_can_bus_state_t state);
const char *eb_can_health_hint(const eb_can_diag_t *diag);

#ifdef __cplusplus
}
#endif

#endif /* EB_CAN_H */
```

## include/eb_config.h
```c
/*
 * Copyright (c) 2026 Nitin Chauhan / EdgeBridge-S3
 * SPDX-License-Identifier: GPL-3.0-only OR LicenseRef-EdgeBridge-Commercial
 */

#ifndef EB_CONFIG_H
#define EB_CONFIG_H

#include <stdbool.h>
#include <stdint.h>

#ifdef __cplusplus
extern "C" {
#endif

#define EB_CONFIG_WATCHDOG_DEFAULT_SEC 60U
#define EB_CONFIG_MAGIC                0x45424346U /* "EBCF" */
#define EB_CONFIG_PERSIST_MAGIC        0x45425053U /* "EBPS" */

typedef struct {
    uint32_t magic;
    uint32_t version;
    uint32_t rs485_baud;
    uint32_t rs485_guard_extra_us;
    bool rs485_auto_direction;
    bool rs485_strict_baud_cap;
    uint32_t can_bitrate;
    uint16_t poll_interval_ms;
    char wifi_ssid[33];
    char wifi_pass[65];
    char mqtt_broker[65];
    uint16_t mqtt_port;
    char active_profile[32];
    bool provisioned;
    uint32_t crc32;
} eb_config_t;

typedef struct {
    uint32_t magic;
    eb_config_t active;
    eb_config_t backup;
    bool pending_confirm;
    uint32_t rollback_count;
    uint32_t crc32;
} eb_config_persist_blob_t;

typedef struct {
    int (*load)(void *ctx, eb_config_persist_blob_t *out_blob);
    int (*save)(void *ctx, const eb_config_persist_blob_t *blob);
    void *ctx;
} eb_config_backend_t;

typedef struct {
    eb_config_t active;
    eb_config_t backup;
    bool pending_confirm;
    uint32_t staged_at_sec;
    uint32_t watchdog_sec;
    uint32_t rollback_count;
    const eb_config_backend_t *backend;
} eb_config_mgr_t;

void eb_config_init(eb_config_mgr_t *mgr, uint32_t watchdog_sec);

/* Load dual-bank config from NVS/file; auto-reverts if pending_confirm survived a crash/reboot. */
int eb_config_attach_backend(eb_config_mgr_t *mgr, const eb_config_backend_t *backend);

uint32_t eb_config_crc32(const eb_config_t *cfg);
bool eb_config_validate(const eb_config_t *cfg);

/* Stage a new config; starts the 60s rollback watchdog and persists pending state. */
int eb_config_stage(eb_config_mgr_t *mgr, const eb_config_t *new_cfg, uint32_t now_sec);

/* Confirm the staged config (e.g., after MQTT/Web UI reachability is verified). */
int eb_config_confirm(eb_config_mgr_t *mgr);

/* Periodic tick; returns true if an automatic rollback occurred. */
bool eb_config_tick(eb_config_mgr_t *mgr, uint32_t now_sec);

/* Remaining seconds before watchdog auto-reverts, or 0 if confirmed. */
uint32_t eb_config_remaining_watchdog_sec(const eb_config_mgr_t *mgr, uint32_t now_sec);

#ifdef __cplusplus
}
#endif

#endif /* EB_CONFIG_H */
```

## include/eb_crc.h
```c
/*
 * Copyright (c) 2026 Nitin Chauhan / EdgeBridge-S3
 * SPDX-License-Identifier: GPL-3.0-only OR LicenseRef-EdgeBridge-Commercial
 */

#ifndef EB_CRC_H
#define EB_CRC_H

#include <stddef.h>
#include <stdint.h>

#ifdef __cplusplus
extern "C" {
#endif

/* Standard IEEE 802.3 CRC-32 (poly 0xEDB88320, init 0xFFFFFFFF, final XOR ~0). */
uint32_t eb_crc32_ieee(const void *data, size_t len);

#ifdef __cplusplus
}
#endif

#endif /* EB_CRC_H */
```

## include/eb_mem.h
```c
/*
 * Copyright (c) 2026 Nitin Chauhan / EdgeBridge-S3
 * SPDX-License-Identifier: GPL-3.0-only OR LicenseRef-EdgeBridge-Commercial
 */

#ifndef EB_MEM_H
#define EB_MEM_H

#include <stdbool.h>
#include <stddef.h>
#include <stdint.h>

#ifdef __cplusplus
extern "C" {
#endif

/*
 * PSRAM placement macro:
 * Routes large telemetry ring buffers, JSON serialization buffers, and HTTP
 * scratch memory into 8 MB Octal PSRAM on ESP32-S3 Zephyr builds so internal
 * SRAM stays below the PRD 35% ceiling even during Wi-Fi + TLS + BLE setup.
 */
#if defined(__ZEPHYR__) && defined(CONFIG_ESP_SPIRAM)
#define EB_PSRAM_BSS __attribute__((section(".ext_ram.bss")))
#else
#define EB_PSRAM_BSS
#endif

#define EB_INTERNAL_SRAM_TARGET_PCT 35U

typedef struct {
    uint32_t internal_sram_total_bytes;
    uint32_t internal_sram_used_bytes;
    uint32_t psram_total_bytes;
    uint32_t psram_used_bytes;
    bool psram_active;
} eb_mem_stats_t;

static inline uint32_t eb_mem_internal_sram_pct(const eb_mem_stats_t *stats) {
    if (!stats || stats->internal_sram_total_bytes == 0U) {
        return 0U;
    }
    return (uint32_t)(((uint64_t)stats->internal_sram_used_bytes * 100ULL) /
                      stats->internal_sram_total_bytes);
}

static inline bool eb_mem_within_sram_budget(const eb_mem_stats_t *stats) {
    return eb_mem_internal_sram_pct(stats) < EB_INTERNAL_SRAM_TARGET_PCT;
}

#ifdef __cplusplus
}
#endif

#endif /* EB_MEM_H */
```

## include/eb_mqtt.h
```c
/*
 * Copyright (c) 2026 Nitin Chauhan / EdgeBridge-S3
 * SPDX-License-Identifier: GPL-3.0-only OR LicenseRef-EdgeBridge-Commercial
 */

#ifndef EB_MQTT_H
#define EB_MQTT_H

#include "eb_profile.h"
#include "eb_storage.h"
#include <stdbool.h>
#include <stddef.h>
#include <stdint.h>

#ifdef __cplusplus
extern "C" {
#endif

typedef struct {
    char device_id[32];
    bool wifi_connected;
    bool mqtt_connected;
    uint32_t published_count;
    uint32_t publish_failures;
    uint32_t reconnect_attempts;
    uint32_t outage_count;
    uint64_t last_publish_ms;
    uint64_t last_reconnect_attempt_ms;
} eb_mqtt_client_t;

typedef int (*eb_mqtt_publish_fn_t)(void *user_ctx, const char *topic,
                                    const char *payload, size_t payload_len);

void eb_mqtt_init(eb_mqtt_client_t *client, const char *device_id);
void eb_mqtt_set_link_state(eb_mqtt_client_t *client, bool wifi_up, bool mqtt_up);
uint32_t eb_mqtt_next_backoff_ms(const eb_mqtt_client_t *client);
bool eb_mqtt_should_reconnect(eb_mqtt_client_t *client, uint64_t now_ms);

/* Serialize one telemetry record (plus matching decoded metrics) into JSON. */
int eb_mqtt_format_record_json(char *out_buf, size_t buf_cap,
                               const char *device_id,
                               const eb_telemetry_record_t *rec,
                               const eb_profile_mgr_t *profiles);

/*
 * FIFO store-and-forward drain: peeks oldest valid records from LittleFS ring
 * and only calls eb_storage_ack_oldest() after publish_fn returns 0 (PUBACK).
 */
size_t eb_mqtt_drain_storage(eb_mqtt_client_t *client,
                             eb_storage_ring_t *storage,
                             const eb_profile_mgr_t *profiles,
                             eb_mqtt_publish_fn_t publish_fn,
                             void *user_ctx,
                             size_t max_batch,
                             char *scratch_buf,
                             size_t scratch_cap);

#ifdef __cplusplus
}
#endif

#endif /* EB_MQTT_H */
```

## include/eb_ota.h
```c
/*
 * Copyright (c) 2026 Nitin Chauhan / EdgeBridge-S3
 * SPDX-License-Identifier: GPL-3.0-only OR LicenseRef-EdgeBridge-Commercial
 */

#ifndef EB_OTA_H
#define EB_OTA_H

#include <stdbool.h>
#include <stddef.h>
#include <stdint.h>

#ifdef __cplusplus
extern "C" {
#endif

typedef enum {
    EB_OTA_IDLE = 0,
    EB_OTA_DOWNLOADING = 1,
    EB_OTA_STAGED_PENDING_REBOOT = 2,
    EB_OTA_FAILED = 3
} eb_ota_download_status_t;

typedef struct {
    int (*begin)(void *ctx, size_t expected_size);
    int (*write_chunk)(void *ctx, size_t offset, const uint8_t *data, size_t len);
    int (*finish_and_request_upgrade)(void *ctx);
    void *ctx;
} eb_ota_flash_ops_t;

typedef struct {
    bool image_confirmed;
    bool network_healthy;
    bool bus_healthy;
    uint32_t boot_count;
    uint32_t required_stable_sec;
    uint32_t healthy_since_sec;
    bool health_timer_armed;

    eb_ota_download_status_t dl_status;
    char pending_url[128];
    size_t expected_size;
    size_t bytes_received;
    uint32_t expected_crc32;
    uint32_t running_crc32;
    const eb_ota_flash_ops_t *flash_ops;
} eb_ota_state_t;

void eb_ota_init(eb_ota_state_t *ota, bool already_confirmed);
void eb_ota_init_with_gate(eb_ota_state_t *ota, bool already_confirmed,
                           uint32_t required_stable_sec,
                           const eb_ota_flash_ops_t *flash_ops);

void eb_ota_report_health(eb_ota_state_t *ota, bool net_ok, bool bus_ok);
void eb_ota_report_health_at(eb_ota_state_t *ota, bool net_ok, bool bus_ok, uint32_t now_sec);

/* Confirms MCUboot slot0 only when network + bus health checks pass (and stability window elapsed). */
bool eb_ota_try_confirm(eb_ota_state_t *ota);
bool eb_ota_try_confirm_at(eb_ota_state_t *ota, uint32_t now_sec);

/* Resumable byte-range OTA staging state machine. */
int eb_ota_begin_download(eb_ota_state_t *ota, const char *url,
                          size_t expected_size, uint32_t expected_crc32);
int eb_ota_ingest_chunk(eb_ota_state_t *ota, size_t offset,
                        const uint8_t *data, size_t len);
int eb_ota_finalize(eb_ota_state_t *ota);
const char *eb_ota_status_str(eb_ota_download_status_t status);

#ifdef __cplusplus
}
#endif

#endif /* EB_OTA_H */
```

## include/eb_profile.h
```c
/*
 * Copyright (c) 2026 Nitin Chauhan / EdgeBridge-S3
 * SPDX-License-Identifier: GPL-3.0-only OR LicenseRef-EdgeBridge-Commercial
 */

#ifndef EB_PROFILE_H
#define EB_PROFILE_H

#include "eb_can.h"
#include "eb_ring_queue.h"
#include <stdbool.h>
#include <stddef.h>
#include <stdint.h>

#ifdef __cplusplus
extern "C" {
#endif

#define EB_PROFILE_MAX_METRICS     16U
#define EB_PROFILE_MAX_ACTIVE      5U   /* e.g. 4 Modbus slaves + 1 CAN BMS */
#define EB_PROFILE_NAME_LEN        32U
#define EB_PROFILE_UNIT_LEN        8U
#define EB_SNAPSHOT_MAX_VALUES     32U

typedef struct {
    char name[EB_PROFILE_NAME_LEN];
    char unit[EB_PROFILE_UNIT_LEN];
    uint8_t slave_id;      /* 0 => inherit profile slave_id */
    uint8_t func;          /* Modbus function 1..4 */
    uint16_t address;      /* Modbus register address */
    uint8_t length;        /* Register count (1 or 2) or CAN bytes (1,2,4) */
    uint32_t can_id;       /* CAN 11/29-bit ID if bus == EB_BUS_CAN */
    uint8_t byte_offset;   /* CAN payload start byte (0..7) */
    bool is_signed;
    bool little_endian;    /* CAN: true for Pylontech/Intel LE; Modbus: false=BE */
    double scale;
} eb_signal_def_t;

typedef struct {
    char profile_id[EB_PROFILE_NAME_LEN];
    char device_name[48];
    eb_bus_type_t bus;
    uint32_t baud_or_bitrate;
    uint8_t slave_id;
    uint16_t poll_interval_ms;
    uint32_t turnaround_guard_us;
    size_t signal_count;
    eb_signal_def_t signals[EB_PROFILE_MAX_METRICS];
} eb_device_profile_t;

typedef struct {
    char profile_id[EB_PROFILE_NAME_LEN];
    char metric_name[EB_PROFILE_NAME_LEN];
    char unit[EB_PROFILE_UNIT_LEN];
    uint8_t bus;
    uint8_t addr;
    uint32_t can_id;
    double value;
    uint64_t timestamp_ms;
    bool valid;
} eb_decoded_value_t;

typedef struct {
    eb_device_profile_t active_profiles[EB_PROFILE_MAX_ACTIVE];
    size_t profile_count;
    eb_decoded_value_t latest[EB_SNAPSHOT_MAX_VALUES];
    size_t latest_count;
} eb_profile_mgr_t;

void eb_profile_mgr_init(eb_profile_mgr_t *mgr);

/* Load a built-in profile by ID (e.g. "jk_bms_modbus_v1", "pylontech_can_v1", "deye_inverter_modbus_v1"). */
int eb_profile_load_builtin(eb_profile_mgr_t *mgr, const char *profile_id, uint8_t slave_override);

/* Parse and register a custom JSON profile matching the profiles JSON schema. */
int eb_profile_load_json(eb_profile_mgr_t *mgr, const char *json_str, size_t json_len);

/* Clear all active profiles and decoded snapshot values. */
void eb_profile_clear(eb_profile_mgr_t *mgr);

/* Number of built-in profiles compiled into firmware. */
size_t eb_profile_builtin_count(void);
const char *eb_profile_builtin_id(size_t idx);
const char *eb_profile_builtin_json(size_t idx);

/* Decode a Modbus reply payload (data bytes after byte_count) for a specific signal. */
int eb_profile_decode_modbus_signal(eb_profile_mgr_t *mgr,
                                    const eb_device_profile_t *prof,
                                    const eb_signal_def_t *sig,
                                    const uint8_t *reg_bytes,
                                    size_t byte_len,
                                    uint64_t timestamp_ms,
                                    eb_decoded_value_t *out_val);

/* Decode any matching signals in active CAN profiles for a received CAN frame. */
size_t eb_profile_decode_can_frame(eb_profile_mgr_t *mgr,
                                   const eb_can_frame_t *frame,
                                   uint64_t timestamp_ms);

#ifdef __cplusplus
}
#endif

#endif /* EB_PROFILE_H */
```

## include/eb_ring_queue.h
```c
/*
 * Copyright (c) 2026 Nitin Chauhan / EdgeBridge-S3
 * SPDX-License-Identifier: GPL-3.0-only OR LicenseRef-EdgeBridge-Commercial
 */

#ifndef EB_RING_QUEUE_H
#define EB_RING_QUEUE_H

#include <stdbool.h>
#include <stddef.h>
#include <stdint.h>

#ifdef __cplusplus
extern "C" {
#endif

#define EB_TELEMETRY_MAX_PAYLOAD 64U

typedef enum {
    EB_BUS_RS485 = 1,
    EB_BUS_CAN   = 2
} eb_bus_type_t;

typedef struct {
    uint64_t timestamp_ms;
    uint32_t seq;
    uint8_t bus;        /* eb_bus_type_t */
    uint8_t addr;       /* Modbus slave ID or CAN node */
    uint16_t len;
    uint32_t can_id;
    uint8_t payload[EB_TELEMETRY_MAX_PAYLOAD];
    uint32_t crc32;
} eb_telemetry_record_t;

/* Lock-free Single-Producer Single-Consumer (SPSC) ring queue */
typedef struct {
    eb_telemetry_record_t *buf;
    size_t capacity;    /* Must be power of 2 */
    volatile size_t head;
    volatile size_t tail;
    uint32_t dropped_count;
} eb_ring_queue_t;

int eb_ring_queue_init(eb_ring_queue_t *q, eb_telemetry_record_t *backing_buf, size_t capacity_pow2);
bool eb_ring_queue_push(eb_ring_queue_t *q, const eb_telemetry_record_t *rec);
bool eb_ring_queue_pop(eb_ring_queue_t *q, eb_telemetry_record_t *out_rec);
size_t eb_ring_queue_count(const eb_ring_queue_t *q);

#ifdef __cplusplus
}
#endif

#endif /* EB_RING_QUEUE_H */
```

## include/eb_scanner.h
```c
/*
 * Copyright (c) 2026 Nitin Chauhan / EdgeBridge-S3
 * SPDX-License-Identifier: GPL-3.0-only OR LicenseRef-EdgeBridge-Commercial
 */

#ifndef EB_SCANNER_H
#define EB_SCANNER_H

#include "eb_rs485.h"
#include <stdbool.h>
#include <stddef.h>
#include <stdint.h>

#ifdef __cplusplus
extern "C" {
#endif

#define EB_SCAN_MAX_RS485_HITS 16U
#define EB_SCAN_MAX_CAN_IDS    16U

typedef struct {
    uint32_t baud_rate;
    uint8_t slave_id;
    uint8_t probe_func;
    uint16_t probe_reg;
    bool is_exception;
    uint8_t exception_code;
} eb_scan_rs485_hit_t;

typedef struct {
    bool scan_completed;
    uint32_t bauds_probed;
    uint32_t probes_sent;
    size_t hit_count;
    eb_scan_rs485_hit_t hits[EB_SCAN_MAX_RS485_HITS];
    uint32_t detected_can_bitrate;
    size_t can_id_count;
    uint32_t can_ids[EB_SCAN_MAX_CAN_IDS];
} eb_scan_result_t;

typedef struct {
    int (*set_listen_bitrate)(void *user_ctx, uint32_t bitrate);
    int (*listen_frames)(void *user_ctx, uint32_t window_ms,
                         uint32_t *out_ids, size_t max_ids, size_t *out_count);
    void *user_ctx;
} eb_can_scan_transport_t;

/*
 * Auto-detect RS-485 baud rates (9600..115200) and Modbus slave IDs.
 * Both EB_RS485_OK and valid-CRC EB_RS485_ERR_EXCEPTION count as live node hits.
 */
int eb_scanner_run_rs485(eb_rs485_ctx_t *rs485,
                         const eb_rs485_transport_t *xp,
                         uint8_t min_slave_id,
                         uint8_t max_slave_id,
                         eb_scan_result_t *out_result);

/*
 * Listen-only CAN bitrate auto-detection across [500000, 250000, 125000, 1000000]
 * so a live solar BMS/inverter bus is never disturbed during commissioning.
 */
int eb_scanner_run_can(const eb_can_scan_transport_t *xp,
                       uint32_t window_per_rate_ms,
                       eb_scan_result_t *out_result);

#ifdef __cplusplus
}
#endif

#endif /* EB_SCANNER_H */
```
